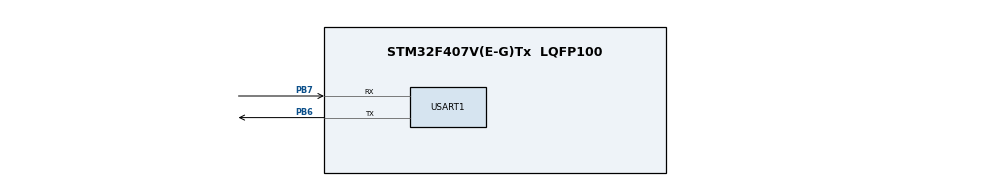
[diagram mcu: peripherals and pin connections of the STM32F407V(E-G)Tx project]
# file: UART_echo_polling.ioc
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Mcu.Family=STM32F4
Mcu.Name=STM32F407V(E-G)Tx
Mcu.Package=LQFP100
NVIC.PriorityGroup=NVIC_PRIORITYGROUP_4
PB6.Mode=Asynchronous
PB6.Signal=USART1_TX
PB7.Mode=Asynchronous
PB7.Signal=USART1_RX
ProjectManager.HeapSize=0x200
ProjectManager.StackSize=0x400
ProjectManager.TargetToolchain=STM32CubeIDE
RCC.AHBFreq_Value=16000000
RCC.APB1Freq_Value=16000000
RCC.APB2Freq_Value=16000000
RCC.CortexFreq_Value=16000000
RCC.HSE_VALUE=25000000
RCC.HSI_VALUE=16000000
RCC.LSE_VALUE=32768
RCC.SYSCLKFreq_VALUE=16000000
RCC.VCOOutputFreq_Value=192000000
USART1.VirtualMode=VM_ASYNC
board=custom

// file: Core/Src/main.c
/* USER CODE BEGIN Header */
/**
  ******************************************************************************
  * @file           : main.c
  * @brief          : Main program body
  ******************************************************************************
  * @attention
  *
  * Copyright (c) 2024 STMicroelectronics.
  * All rights reserved.
  *
  * This software is licensed under terms that can be found in the LICENSE file
  * in the root directory of this software component.
  * If no LICENSE file comes with this software, it is provided AS-IS.
  *
  ******************************************************************************
  */
/* USER CODE END Header */
#include "main.h"

void SystemClock_Config(void);
static void MX_GPIO_Init(void);
static void MX_USART1_UART_Init(void);

int main(void)
{

  /* MCU Configuration--------------------------------------------------------*/

  /* Reset of all peripherals, Initializes the Flash interface and the Systick. */
  LL_APB2_GRP1_EnableClock(LL_APB2_GRP1_PERIPH_SYSCFG);
  LL_APB1_GRP1_EnableClock(LL_APB1_GRP1_PERIPH_PWR);

  /* System interrupt init*/
  NVIC_SetPriorityGrouping(NVIC_PRIORITYGROUP_4);

  /* SysTick_IRQn interrupt configuration */
  NVIC_SetPriority(SysTick_IRQn, NVIC_EncodePriority(NVIC_GetPriorityGrouping(),15, 0));

  /* Configure the system clock */
  SystemClock_Config();

  /* Initialize all configured peripherals */
  MX_GPIO_Init();
  MX_USART1_UART_Init();

  /* Infinite loop */
  while (1)
  {

    /* USER CODE BEGIN 3 */
	  if (LL_USART_IsActiveFlag_RXNE(USART1))
	  {
		  LL_USART_TransmitData8(USART1, LL_USART_ReceiveData8(USART1));
	  }
  }
  /* USER CODE END 3 */
}

void SystemClock_Config(void)
{
  LL_FLASH_SetLatency(LL_FLASH_LATENCY_0);
  while(LL_FLASH_GetLatency()!= LL_FLASH_LATENCY_0)
  {
  }
  LL_PWR_SetRegulVoltageScaling(LL_PWR_REGU_VOLTAGE_SCALE1);
  LL_RCC_HSI_SetCalibTrimming(16);
  LL_RCC_HSI_Enable();

   /* Wait till HSI is ready */
  while(LL_RCC_HSI_IsReady() != 1)
  {

  }
  LL_RCC_SetAHBPrescaler(LL_RCC_SYSCLK_DIV_1);
  LL_RCC_SetAPB1Prescaler(LL_RCC_APB1_DIV_1);
  LL_RCC_SetAPB2Prescaler(LL_RCC_APB2_DIV_1);
  LL_RCC_SetSysClkSource(LL_RCC_SYS_CLKSOURCE_HSI);

   /* Wait till System clock is ready */
  while(LL_RCC_GetSysClkSource() != LL_RCC_SYS_CLKSOURCE_STATUS_HSI)
  {

  }
  LL_Init1msTick(16000000);
  LL_SetSystemCoreClock(16000000);
}

static void MX_USART1_UART_Init(void)
{

  LL_USART_InitTypeDef USART_InitStruct = {0};

  LL_GPIO_InitTypeDef GPIO_InitStruct = {0};

  /* Peripheral clock enable */
  LL_APB2_GRP1_EnableClock(LL_APB2_GRP1_PERIPH_USART1);

  LL_AHB1_GRP1_EnableClock(LL_AHB1_GRP1_PERIPH_GPIOB);
  /**USART1 GPIO Configuration
  PB6   ------> USART1_TX
  PB7   ------> USART1_RX
  */
  GPIO_InitStruct.Pin = LL_GPIO_PIN_6|LL_GPIO_PIN_7;
  GPIO_InitStruct.Mode = LL_GPIO_MODE_ALTERNATE;
  GPIO_InitStruct.Speed = LL_GPIO_SPEED_FREQ_VERY_HIGH;
  GPIO_InitStruct.OutputType = LL_GPIO_OUTPUT_PUSHPULL;
  GPIO_InitStruct.Pull = LL_GPIO_PULL_NO;
  GPIO_InitStruct.Alternate = LL_GPIO_AF_7;
  LL_GPIO_Init(GPIOB, &GPIO_InitStruct);

  USART_InitStruct.BaudRate = 115200;
  USART_InitStruct.DataWidth = LL_USART_DATAWIDTH_8B;
  USART_InitStruct.StopBits = LL_USART_STOPBITS_1;
  USART_InitStruct.Parity = LL_USART_PARITY_NONE;
  USART_InitStruct.TransferDirection = LL_USART_DIRECTION_TX_RX;
  USART_InitStruct.HardwareFlowControl = LL_USART_HWCONTROL_NONE;
  USART_InitStruct.OverSampling = LL_USART_OVERSAMPLING_16;
  LL_USART_Init(USART1, &USART_InitStruct);
  LL_USART_ConfigAsyncMode(USART1);
  LL_USART_Enable(USART1);

}

static void MX_GPIO_Init(void)
{

  /* GPIO Ports Clock Enable */
  LL_AHB1_GRP1_EnableClock(LL_AHB1_GRP1_PERIPH_GPIOB);

}

void Error_Handler(void)
{
  __disable_irq();
  while (1)
  {
  }
}
